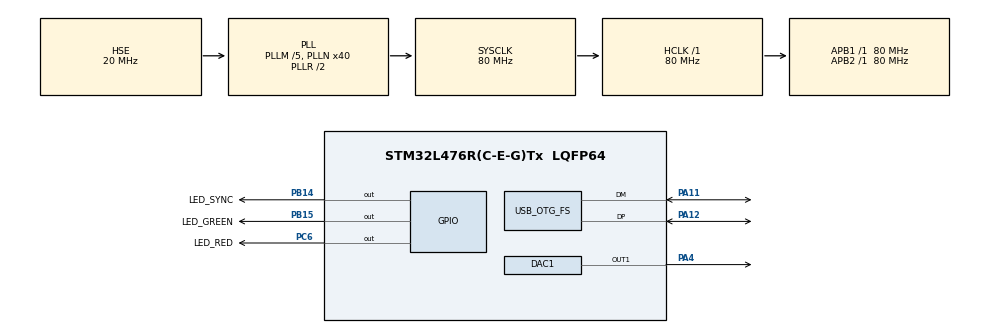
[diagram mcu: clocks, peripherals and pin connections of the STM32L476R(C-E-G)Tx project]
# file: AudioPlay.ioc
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DAC1.DAC_Trigger-DAC_OUT1=DAC_TRIGGER_T6_TRGO
Dma.DAC_CH1.0.Direction=DMA_MEMORY_TO_PERIPH
Dma.DAC_CH1.0.Instance=DMA1_Channel3
Dma.DAC_CH1.0.MemDataAlignment=DMA_MDATAALIGN_HALFWORD
Dma.DAC_CH1.0.MemInc=DMA_MINC_ENABLE
Dma.DAC_CH1.0.Mode=DMA_NORMAL
Dma.DAC_CH1.0.NoTestForDmaSupport=false
Dma.DAC_CH1.0.PeriphDataAlignment=DMA_PDATAALIGN_HALFWORD
Dma.DAC_CH1.0.PeriphInc=DMA_PINC_DISABLE
Dma.DAC_CH1.0.Priority=DMA_PRIORITY_LOW
Dma.DAC_CH1.0.Request=DMA_REQUEST_6
Dma.Request0=DAC_CH1
Mcu.Family=STM32L4
Mcu.Name=STM32L476R(C-E-G)Tx
Mcu.Package=LQFP64
NVIC.DMA1_Channel3_IRQn=true\:0\:0\:false\:false\:true
NVIC.OTG_FS_IRQn=true\:0\:0\:false\:false\:true
NVIC.PriorityGroup=NVIC_PRIORITYGROUP_4
PA11.Mode=Device_Only
PA11.Signal=USB_OTG_FS_DM
PA12.Mode=Device_Only
PA12.Signal=USB_OTG_FS_DP
PA13.Mode=Serial-Wire
PA13.Signal=SYS_JTMS-SWDIO
PA14.Mode=Serial-Wire
PA14.Signal=SYS_JTCK-SWCLK
PA4.Signal=COMP_DAC11_group
PB14.GPIO_Label=LED_SYNC
PB14.Signal=GPIO_Output
PB15.GPIO_Label=LED_GREEN
PB15.Signal=GPIO_Output
PC6.GPIO_Label=LED_RED
PC6.Signal=GPIO_Output
PH0/OSC_IN.Mode=HSE-External-Clock-Source
PH0/OSC_IN.Signal=RCC_OSC_IN
ProjectManager.HeapSize=0x400
ProjectManager.StackSize=0x600
ProjectManager.TargetToolchain=SW4STM32
RCC.ADCFreq_Value=48000000
RCC.AHBFreq_Value=80000000
RCC.APB1Freq_Value=80000000
RCC.APB1TimFreq_Value=80000000
RCC.APB2Freq_Value=80000000
RCC.APB2TimFreq_Value=80000000
RCC.CortexFreq_Value=80000000
RCC.HCLKFreq_Value=80000000
RCC.HSE_VALUE=20000000
RCC.HSI_VALUE=16000000
RCC.LSE_VALUE=32768
RCC.MSI_VALUE=4000000
RCC.PLLM=5
RCC.PLLN=40
RCC.PLLSAI1N=24
RCC.PLLSourceVirtual=RCC_PLLSOURCE_HSE
RCC.SYSCLKFreq_VALUE=80000000
RCC.SYSCLKSource=RCC_SYSCLKSOURCE_PLLCLK
RCC.USBFreq_Value=48000000
RCC.VCOOutputFreq_Value=160000000
SH.COMP_DAC11_group.0=DAC1_OUT1,DAC_OUT1
TIM6.Period=3628
TIM6.Prescaler=0
TIM6.TIM_MasterOutputTrigger=TIM_TRGO_UPDATE
USB_DEVICE.CLASS_NAME_FS=CDC
USB_DEVICE.MANUFACTURER_STRING=Vanderbilt University
USB_DEVICE.PRODUCT_STRING_CDC_FS=ChronoCape GPSBridge
USB_DEVICE.USBD_HandleTypeDef=hUsbDeviceFS
USB_DEVICE.VirtualMode=Cdc
USB_DEVICE.VirtualModeFS=Cdc_FS
USB_OTG_FS.VirtualMode=Device_Only
USB_OTG_FS.vbus_sensing_enable=DISABLE
VP_TIM6_VS_ClockSourceINT.Mode=Enable_Timer
VP_USB_DEVICE_VS_USB_DEVICE_CDC_FS.Mode=CDC_FS
board=AudioPlay

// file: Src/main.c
/**
  ******************************************************************************
  * File Name          : main.c
  * Description        : Main program body
  ******************************************************************************
  *
  * COPYRIGHT(c) 2016 STMicroelectronics
  *
  * Redistribution and use in source and binary forms, with or without modification,
  * are permitted provided that the following conditions are met:
  *   1. Redistributions of source code must retain the above copyright notice,
  *      this list of conditions and the following disclaimer.
  *   2. Redistributions in binary form must reproduce the above copyright notice,
  *      this list of conditions and the following disclaimer in the documentation
  *      and/or other materials provided with the distribution.
  *   3. Neither the name of STMicroelectronics nor the names of its contributors
  *      may be used to endorse or promote products derived from this software
  *      without specific prior written permission.
  *
  * THIS SOFTWARE IS PROVIDED BY THE COPYRIGHT HOLDERS AND CONTRIBUTORS "AS IS"
  * AND ANY EXPRESS OR IMPLIED WARRANTIES, INCLUDING, BUT NOT LIMITED TO, THE
  * IMPLIED WARRANTIES OF MERCHANTABILITY AND FITNESS FOR A PARTICULAR PURPOSE ARE
  * DISCLAIMED. IN NO EVENT SHALL THE COPYRIGHT HOLDER OR CONTRIBUTORS BE LIABLE
  * FOR ANY DIRECT, INDIRECT, INCIDENTAL, SPECIAL, EXEMPLARY, OR CONSEQUENTIAL
  * DAMAGES (INCLUDING, BUT NOT LIMITED TO, PROCUREMENT OF SUBSTITUTE GOODS OR
  * SERVICES; LOSS OF USE, DATA, OR PROFITS; OR BUSINESS INTERRUPTION) HOWEVER
  * CAUSED AND ON ANY THEORY OF LIABILITY, WHETHER IN CONTRACT, STRICT LIABILITY,
  * OR TORT (INCLUDING NEGLIGENCE OR OTHERWISE) ARISING IN ANY WAY OUT OF THE USE
  * OF THIS SOFTWARE, EVEN IF ADVISED OF THE POSSIBILITY OF SUCH DAMAGE.
  *
  ******************************************************************************
  */
#include "stm32l4xx_hal.h"
#include "usb_device.h"

/* USER CODE BEGIN Includes */
#define AUDIO_FILE_ADDRESS   0x08080000
#define AUDIO_FILE_SIZE      (106150)

/* USER CODE END Includes */

DAC_HandleTypeDef hdac1;
DMA_HandleTypeDef hdma_dac_ch1;

TIM_HandleTypeDef htim6;

/* USER CODE BEGIN PV */
/* Private variables ---------------------------------------------------------*/

/* USER CODE END PV */

void SystemClock_Config(void);
static void MX_GPIO_Init(void);
static void MX_DMA_Init(void);
static void MX_DAC1_Init(void);
static void MX_TIM6_Init(void);

/* USER CODE BEGIN PFP */
/* Private function prototypes -----------------------------------------------*/

/* USER CODE END PFP */

int main(void)
{

  /* MCU Configuration----------------------------------------------------------*/

  /* Reset of all peripherals, Initializes the Flash interface and the Systick. */
  HAL_Init();

  /* Configure the system clock */
  SystemClock_Config();

  /* Initialize all configured peripherals */
  MX_GPIO_Init();
  MX_DMA_Init();
  MX_USB_DEVICE_Init();
  MX_DAC1_Init();
  MX_TIM6_Init();

  /* USER CODE BEGIN 2 */
  HAL_Delay(4000);
  HAL_DAC_Start_DMA(&hdac1, DAC_CHANNEL_1, (uint32_t*)AUDIO_FILE_ADDRESS, AUDIO_FILE_SIZE, DAC_ALIGN_12B_L);
  HAL_TIM_Base_Start(&htim6);
  /* USER CODE END 2 */

  /* Infinite loop */
  while (1)
  {

  }

}

/** System Clock Configuration
*/
void SystemClock_Config(void)
{

  RCC_OscInitTypeDef RCC_OscInitStruct;
  RCC_ClkInitTypeDef RCC_ClkInitStruct;
  RCC_PeriphCLKInitTypeDef PeriphClkInit;

  RCC_OscInitStruct.OscillatorType = RCC_OSCILLATORTYPE_HSE;
  RCC_OscInitStruct.HSEState = RCC_HSE_BYPASS;
  RCC_OscInitStruct.PLL.PLLState = RCC_PLL_ON;
  RCC_OscInitStruct.PLL.PLLSource = RCC_PLLSOURCE_HSE;
  RCC_OscInitStruct.PLL.PLLM = 5;
  RCC_OscInitStruct.PLL.PLLN = 40;
  RCC_OscInitStruct.PLL.PLLP = RCC_PLLP_DIV7;
  RCC_OscInitStruct.PLL.PLLQ = RCC_PLLQ_DIV2;
  RCC_OscInitStruct.PLL.PLLR = RCC_PLLR_DIV2;
  HAL_RCC_OscConfig(&RCC_OscInitStruct);

  RCC_ClkInitStruct.ClockType = RCC_CLOCKTYPE_HCLK|RCC_CLOCKTYPE_SYSCLK
                              |RCC_CLOCKTYPE_PCLK1|RCC_CLOCKTYPE_PCLK2;
  RCC_ClkInitStruct.SYSCLKSource = RCC_SYSCLKSOURCE_PLLCLK;
  RCC_ClkInitStruct.AHBCLKDivider = RCC_SYSCLK_DIV1;
  RCC_ClkInitStruct.APB1CLKDivider = RCC_HCLK_DIV1;
  RCC_ClkInitStruct.APB2CLKDivider = RCC_HCLK_DIV1;
  HAL_RCC_ClockConfig(&RCC_ClkInitStruct, FLASH_LATENCY_4);

  PeriphClkInit.PeriphClockSelection = RCC_PERIPHCLK_USB;
  PeriphClkInit.UsbClockSelection = RCC_USBCLKSOURCE_PLLSAI1;
  PeriphClkInit.PLLSAI1.PLLSAI1N = 24;
  PeriphClkInit.PLLSAI1.PLLSAI1P = RCC_PLLP_DIV7;
  PeriphClkInit.PLLSAI1.PLLSAI1Q = RCC_PLLQ_DIV2;
  PeriphClkInit.PLLSAI1.PLLSAI1R = RCC_PLLR_DIV2;
  PeriphClkInit.PLLSAI1.PLLSAI1ClockOut = RCC_PLLSAI1_48M2CLK;
  HAL_RCCEx_PeriphCLKConfig(&PeriphClkInit);

  __HAL_RCC_PWR_CLK_ENABLE();

  HAL_PWREx_ControlVoltageScaling(PWR_REGULATOR_VOLTAGE_SCALE1);

  HAL_SYSTICK_Config(HAL_RCC_GetHCLKFreq()/1000);

  HAL_SYSTICK_CLKSourceConfig(SYSTICK_CLKSOURCE_HCLK);

  /* SysTick_IRQn interrupt configuration */
  HAL_NVIC_SetPriority(SysTick_IRQn, 0, 0);
}

/* DAC1 init function */
void MX_DAC1_Init(void)
{

  DAC_ChannelConfTypeDef sConfig;

    /**DAC Initialization
    */
  hdac1.Instance = DAC1;
  HAL_DAC_Init(&hdac1);

    /**DAC channel OUT1 config
    */
  sConfig.DAC_SampleAndHold = DAC_SAMPLEANDHOLD_DISABLE;
  sConfig.DAC_Trigger = DAC_TRIGGER_T6_TRGO;
  sConfig.DAC_OutputBuffer = DAC_OUTPUTBUFFER_ENABLE;
  sConfig.DAC_ConnectOnChipPeripheral = DAC_CHIPCONNECT_DISABLE;
  sConfig.DAC_UserTrimming = DAC_TRIMMING_FACTORY;
  HAL_DAC_ConfigChannel(&hdac1, &sConfig, DAC_CHANNEL_1);

}

/* TIM6 init function */
void MX_TIM6_Init(void)
{

  TIM_MasterConfigTypeDef sMasterConfig;

  htim6.Instance = TIM6;
  htim6.Init.Prescaler = 0;
  htim6.Init.CounterMode = TIM_COUNTERMODE_UP;
  htim6.Init.Period = 3628;
  HAL_TIM_Base_Init(&htim6);

  sMasterConfig.MasterOutputTrigger = TIM_TRGO_UPDATE;
  sMasterConfig.MasterSlaveMode = TIM_MASTERSLAVEMODE_DISABLE;
  HAL_TIMEx_MasterConfigSynchronization(&htim6, &sMasterConfig);

}

void MX_DMA_Init(void)
{
  /* DMA controller clock enable */
  __HAL_RCC_DMA1_CLK_ENABLE();

  /* DMA interrupt init */
  /* DMA1_Channel3_IRQn interrupt configuration */
  HAL_NVIC_SetPriority(DMA1_Channel3_IRQn, 0, 0);
  HAL_NVIC_EnableIRQ(DMA1_Channel3_IRQn);

}

/** Configure pins as
        * Analog
        * Input
        * Output
        * EVENT_OUT
        * EXTI
*/
void MX_GPIO_Init(void)
{

  GPIO_InitTypeDef GPIO_InitStruct;

  /* GPIO Ports Clock Enable */
  __HAL_RCC_GPIOH_CLK_ENABLE();
  __HAL_RCC_GPIOA_CLK_ENABLE();
  __HAL_RCC_GPIOB_CLK_ENABLE();
  __HAL_RCC_GPIOC_CLK_ENABLE();

  /*Configure GPIO pin Output Level */
  HAL_GPIO_WritePin(GPIOB, LED_SYNC_Pin|LED_GREEN_Pin, GPIO_PIN_RESET);

  /*Configure GPIO pin Output Level */
  HAL_GPIO_WritePin(LED_RED_GPIO_Port, LED_RED_Pin, GPIO_PIN_RESET);

  /*Configure GPIO pins : LED_SYNC_Pin LED_GREEN_Pin */
  GPIO_InitStruct.Pin = LED_SYNC_Pin|LED_GREEN_Pin;
  GPIO_InitStruct.Mode = GPIO_MODE_OUTPUT_PP;
  GPIO_InitStruct.Pull = GPIO_NOPULL;
  GPIO_InitStruct.Speed = GPIO_SPEED_FREQ_LOW;
  HAL_GPIO_Init(GPIOB, &GPIO_InitStruct);

  /*Configure GPIO pin : LED_RED_Pin */
  GPIO_InitStruct.Pin = LED_RED_Pin;
  GPIO_InitStruct.Mode = GPIO_MODE_OUTPUT_PP;
  GPIO_InitStruct.Pull = GPIO_NOPULL;
  GPIO_InitStruct.Speed = GPIO_SPEED_FREQ_LOW;
  HAL_GPIO_Init(LED_RED_GPIO_Port, &GPIO_InitStruct);

}

/************************ (C) COPYRIGHT STMicroelectronics *****END OF FILE****/
